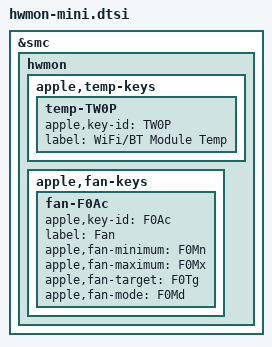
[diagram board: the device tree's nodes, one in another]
// SPDX-License-Identifier: GPL-2.0+ OR MIT
/*
 * hwmon sensors common to the Mac mini desktop
 * models, but not the Studio or Pro.
 *
 * Copyright The Asahi Linux Contributors
 */

&smc {
	hwmon {
		apple,temp-keys {
			temp-TW0P {
				apple,key-id = "TW0P";
				label = "WiFi/BT Module Temp";
			};
		};
		apple,fan-keys {
			fan-F0Ac {
				apple,key-id = "F0Ac";
				label = "Fan";
				apple,fan-minimum = "F0Mn";
				apple,fan-maximum = "F0Mx";
				apple,fan-target = "F0Tg";
				apple,fan-mode = "F0Md";
			};
		};
	};
};
